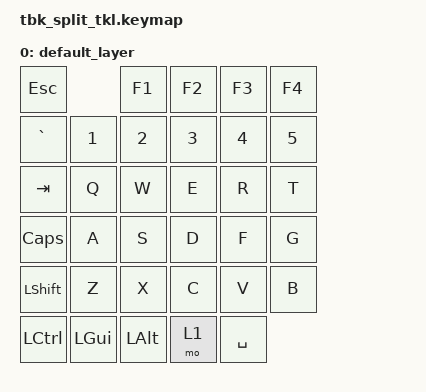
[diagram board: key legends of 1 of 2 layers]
/*
 * Copyright (c) 2021 The ZMK Contributors
 *
 * SPDX-License-Identifier: MIT
 */

#include <behaviors.dtsi>
#include <dt-bindings/zmk/bt.h>
#include <dt-bindings/zmk/keys.h>
#include <dt-bindings/zmk/rgb.h>

/ {
    keymap {
        compatible = "zmk,keymap";

// -------------------------------------          -----------------------------------------------------
// | ESC |     |  F1 |  F2 |  F3 |  F4 |          |  F5 |  F6 |  F7 |  F8 |   |  F9 | F10 | F11 | F12 |
// |  `  |  1  |  2  |  3  |  4  |  5  |        |  6  |  7  |  8  |  9  |  0  |  -  |  =  |  BSPC     |
// | TAB   |  Q  |  W  |  E  |  R  |  T  |        |  Y  |  U  |  I  |  O  |  P  |  [  |  ]  |   \     |
// | CAPS   |  A  |  S  |  D  |  F  |  G  |        |  H  |  J  |  K  |  L  |  ;  |  '  |    ENTER     |
// | SHIFT    |  Z  |  X  |  C  |  V  |  B  |        |  N  |  M  |  ,  |  .  |  /  |        RSHFT     |
// |LCTRL| LGUI| LALT| FN1 |     SPACE      |        |   SPACE        | RALT | RGUI | MENU | RCTRL |
// -------------------------------------------       -----------------------------------------------

        default_layer {
            bindings = <
    &kp ESC            &kp F1   &kp F2    &kp F3    &kp F4  /**/
    &kp GRAVE &kp N1   &kp N2   &kp N3    &kp N4    &kp N5  /**/
    &kp TAB   &kp Q    &kp W    &kp E     &kp R     &kp T   /**/
    &kp CAPS  &kp A    &kp S    &kp D     &kp F     &kp G   /**/
    &kp LSHFT &kp Z    &kp X    &kp C     &kp V     &kp B   /**/
    &kp LCTRL &kp LGUI &kp LALT &mo 1     &kp SPACE         /**/
            >;
        };

// ----------------------------------------------      ----------------------------------------------
// | 1    |  2  |  3  |  4  |  5  |  6  |              |  7  |  8  |  9  |  O  | PSCR |     |  DEL  |
// | `      |     |  <- |  ^   |  -> |  Vo+ |             |  [  |  ]  |  -  |  =  |  ;  |      \    |
// | trans     |     |     |     |  V  |  Vo- |              |     |     |    |     |     |  trans  |
// | trans   | trans| trans |   trans        |             |   trans   | trans | trans | trans|trans|
// -------------------------------------------        -----------------------------------------------

        right_layer {
            bindings = <
    &trans             &kp F5   &kp F6    &kp F7    &kp F8    /**/
    &kp GRAVE &kp N6   &kp N7   &kp N8    &kp N9    &kp N0    /**/
    &kp BSPC  &kp Y    &kp U    &kp I     &kp O     &kp P     /**/
    &kp ENTER &kp H    &kp J    &kp K     &kp L     &kp ;     /**/
    &kp RSHFT &kp N    &kp M    &kp COMMA &kp DOT   &kp SLASH /**/
    &kp RCTRL &kp RGUI &kp RALT &kp K_CMENU         &trans           /**/
            >;
        };

// ----------------------------------------------      ----------------------------------------------
// | F1   |  F2 |  F3 |  F4 | F5  |  F6 |              |  F7 |  F8  | F9  | F1O  | F11 |    |  F12  |
// | CAP      |     | home| PgUp | End |     |           |     |     |     |     |        |         |
// | trans     |  RGB T  |  RGB M   | PgDn |      |     | BT_NXT | BT_CLR |    |    |    |    |trans|
// | trans   | trans| trans |   trans        |           | trans   | trans | trans | trans | trans  |
// -------------------------------------------        -----------------------------------------------
/*
        fn_layer {
            bindings = <
    &kp F1     &kp F2          &kp F3          &kp F4    &kp F5     &kp F6    /**/ &kp F7     &kp F8     &kp F9    &kp F10    &kp F11    &none  &kp F12
    &kp CAPS   &none           &kp HOME        &kp PG_UP &kp END    &none     /**/ &none      &none      &none     &none     &none      &none
    &trans     &rgb_ug RGB_TOG &rgb_ug RGB_EFF &none     &kp PG_DN  &none     /**/ &bt BT_NXT &bt BT_CLR &none     &none     &none      &trans
    &trans     &trans          &trans          &none     &trans               /**/ &trans                &trans    &trans    &trans     &trans
            >;
        };
*/
    };
};
